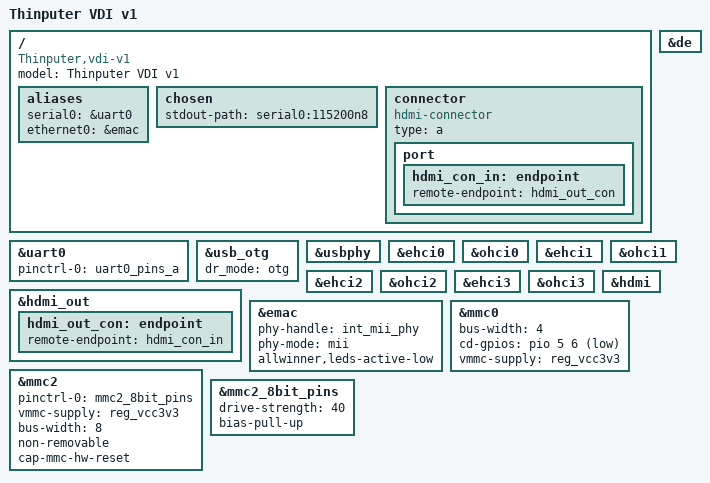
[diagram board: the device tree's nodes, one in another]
/*
 * Copyright (C) 2016 Milo Kim <woogyom.kim@gmail.com>
 *
 * This file is dual-licensed: you can use it either under the terms
 * of the GPL or the X11 license, at your option. Note that this dual
 * licensing only applies to this file, and not this project as a
 * whole.
 *
 *  a) This file is free software; you can redistribute it and/or
 *     modify it under the terms of the GNU General Public License as
 *     published by the Free Software Foundation; either version 2 of the
 *     License, or (at your option) any later version.
 *
 *     This file is distributed in the hope that it will be useful,
 *     but WITHOUT ANY WARRANTY; without even the implied warranty of
 *     MERCHANTABILITY or FITNESS FOR A PARTICULAR PURPOSE.  See the
 *     GNU General Public License for more details.
 *
 * Or, alternatively,
 *
 *  b) Permission is hereby granted, free of charge, to any person
 *     obtaining a copy of this software and associated documentation
 *     files (the "Software"), to deal in the Software without
 *     restriction, including without limitation the rights to use,
 *     copy, modify, merge, publish, distribute, sublicense, and/or
 *     sell copies of the Software, and to permit persons to whom the
 *     Software is furnished to do so, subject to the following
 *     conditions:
 *
 *     The above copyright notice and this permission notice shall be
 *     included in all copies or substantial portions of the Software.
 *
 *     THE SOFTWARE IS PROVIDED "AS IS", WITHOUT WARRANTY OF ANY KIND,
 *     EXPRESS OR IMPLIED, INCLUDING BUT NOT LIMITED TO THE WARRANTIES
 *     OF MERCHANTABILITY, FITNESS FOR A PARTICULAR PURPOSE AND
 *     NONINFRINGEMENT. IN NO EVENT SHALL THE AUTHORS OR COPYRIGHT
 *     HOLDERS BE LIABLE FOR ANY CLAIM, DAMAGES OR OTHER LIABILITY,
 *     WHETHER IN AN ACTION OF CONTRACT, TORT OR OTHERWISE, ARISING
 *     FROM, OUT OF OR IN CONNECTION WITH THE SOFTWARE OR THE USE OR
 *     OTHER DEALINGS IN THE SOFTWARE.
 */

/dts-v1/;
#include "sun8i-h3.dtsi"
#include "sunxi-common-regulators.dtsi"

#include <dt-bindings/gpio/gpio.h>
#include <dt-bindings/input/input.h>

/ {
	model = "Thinputer VDI v1";
	compatible = "Thinputer,vdi-v1", "allwinner,sun8i-h3";

	aliases {
		serial0 = &uart0;
		ethernet0 = &emac;
	};

	chosen {
		stdout-path = "serial0:115200n8";
	};

	connector {
		compatible = "hdmi-connector";
		type = "a";

		port {
			hdmi_con_in: endpoint {
				remote-endpoint = <&hdmi_out_con>;
			};
		};
	};
};

&uart0 {
	pinctrl-names = "default";
	pinctrl-0 = <&uart0_pins_a>;
	status = "okay";
};

&de {
	status = "okay";
};

&usb_otg {
	// OTG is not stable.
	// most nanopi-h3's MicroUSB support OTG, except:
	// 1. nanopi-neo-V1.4 support OTG, nanopi-neo-V1.3/1.2... support USB device.
	// 2. nanopi-k1 only use as power.
	dr_mode = "otg";
	status = "okay";
};

&usbphy {
	status = "okay";
};

&ehci0 {
	status = "okay";
};

&ohci0 {
	status = "okay";
};

&ehci1 {
	status = "okay";
};

&ohci1 {
	status = "okay";
};

&ehci2 {
	status = "okay";
};

&ohci2 {
	status = "okay";
};

&ehci3 {
	status = "okay";
};

&ohci3 {
	status = "okay";
};

&hdmi {
	status = "okay";
};

&hdmi_out {
	hdmi_out_con: endpoint {
		remote-endpoint = <&hdmi_con_in>;
	};
};

&emac {
	phy-handle = <&int_mii_phy>;
	phy-mode = "mii";
	allwinner,leds-active-low;
	status = "okay";
};

&mmc0 {
	bus-width = <4>;
	cd-gpios = <&pio 5 6 GPIO_ACTIVE_LOW>;
	status = "okay";
	vmmc-supply = <&reg_vcc3v3>;
};

// &mmc1 {
// 	vmmc-supply = <&reg_vcc3v3>;
// 	mmc-pwrseq = <&wifi_pwrseq>;
// 	bus-width = <4>;
// 	non-removable;
// 	status = "okay";

// 	/*
// 	 * Explicitly define the sdio device, so that we can add an ethernet
// 	 * alias for it (which e.g. makes u-boot set a mac-address).
// 	 */
// 	rtl8189ftv: sdio_wifi@1 {
// 		reg = <1>;
// 	};
// };

&mmc2 {
	pinctrl-names = "default";
	pinctrl-0 = <&mmc2_8bit_pins>;
	vmmc-supply = <&reg_vcc3v3>;
	bus-width = <8>;
	non-removable;
	cap-mmc-hw-reset;
	status = "okay";
};

&mmc2_8bit_pins {
	/* Increase drive strength for DDR modes */
	drive-strength = <40>;
	/* eMMC is missing pull-ups */
	bias-pull-up;
};
